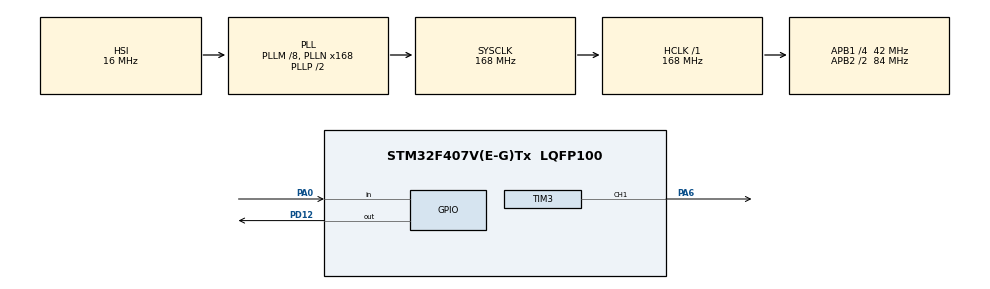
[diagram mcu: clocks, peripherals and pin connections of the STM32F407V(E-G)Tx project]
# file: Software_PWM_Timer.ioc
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Mcu.Family=STM32F4
VP_SYS_VS_tim6.Mode=TIM6
PH0-OSC_IN.Signal=RCC_OSC_IN
RCC.CortexFreq_Value=168000000
FREERTOS.Tasks01=PWMTask,0,128,StartPWMTask,Default,NULL,Dynamic,NULL,NULL
NVIC.TIM6_DAC_IRQn=true\:0\:0\:false\:false\:true\:false\:false\:true
RCC.APB1CLKDivider=RCC_HCLK_DIV4
RCC.SYSCLKSource=RCC_SYSCLKSOURCE_PLLCLK
ProjectManager.StackSize=0x400
PA0-WKUP.Signal=GPIO_Input
ProjectManager.TargetToolchain=STM32CubeIDE
RCC.HCLKFreq_Value=168000000
RCC.APB2TimFreq_Value=168000000
TIM3.Period=100-1
RCC.LSE_VALUE=32768
RCC.AHBFreq_Value=168000000
PH0-OSC_IN.Mode=HSE-External-Oscillator
TIM3.Channel-PWM\ Generation1\ CH1=TIM_CHANNEL_1
RCC.HSE_VALUE=25000000
FREERTOS.configUSE_TIMERS=1
board=custom
RCC.VCOOutputFreq_Value=336000000
RCC.APB2Freq_Value=84000000
TIM3.Prescaler=168-1
PH1-OSC_OUT.Signal=RCC_OSC_OUT
SH.S_TIM3_CH1.0=TIM3_CH1,PWM Generation1 CH1
VP_FREERTOS_VS_CMSIS_V1.Mode=CMSIS_V1
Mcu.Name=STM32F407V(E-G)Tx
FREERTOS.configTIMER_TASK_PRIORITY=6
PH1-OSC_OUT.Mode=HSE-External-Oscillator
RCC.48MHZClocksFreq_Value=84000000
RCC.SYSCLKFreq_VALUE=168000000
Mcu.Package=LQFP100
PA6.Signal=S_TIM3_CH1
NVIC.TimeBase=TIM6_DAC_IRQn
PD12.Signal=GPIO_Output
NVIC.TimeBaseIP=TIM6
ProjectManager.HeapSize=0x200
FREERTOS.Timers01=PeriodicTimer,PTCallback,osTimerPeriodic,Default,NULL,Dynamic,NULL
RCC.HSI_VALUE=16000000
NVIC.PriorityGroup=NVIC_PRIORITYGROUP_4
RCC.APB2CLKDivider=RCC_HCLK_DIV2
RCC.PLLM=8
RCC.PLLN=168
RCC.APB1TimFreq_Value=84000000
RCC.APB1Freq_Value=42000000
VP_TIM3_VS_ClockSourceINT.Mode=Internal

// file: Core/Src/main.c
/* USER CODE BEGIN Header */
/**
  ******************************************************************************
  * @file           : main.c
  * @brief          : Main program body
  ******************************************************************************
  * @attention
  *
  * <h2><center>&copy; Copyright (c) 2021 STMicroelectronics.
  * All rights reserved.</center></h2>
  *
  * This software component is licensed by ST under BSD 3-Clause license,
  * the "License"; You may not use this file except in compliance with the
  * License. You may obtain a copy of the License at:
  *                        opensource.org/licenses/BSD-3-Clause
  *
  ******************************************************************************
  */
/* USER CODE END Header */
#include "main.h"
#include "cmsis_os.h"

/* USER CODE BEGIN PM */
uint16_t increment;
/* USER CODE END PM */

TIM_HandleTypeDef htim3;

osThreadId PWMTaskHandle;
osTimerId PeriodicTimerHandle;

void SystemClock_Config(void);
static void MX_GPIO_Init(void);
static void MX_TIM3_Init(void);
void StartPWMTask(void const * argument);
void PTCallback(void const * argument);

int main(void)
{

  /* MCU Configuration--------------------------------------------------------*/

  /* Reset of all peripherals, Initializes the Flash interface and the Systick. */
  HAL_Init();

  /* Configure the system clock */
  SystemClock_Config();

  /* Initialize all configured peripherals */
  MX_GPIO_Init();
  MX_TIM3_Init();

  /* Create the timer(s) */
  /* definition and creation of PeriodicTimer */
  osTimerDef(PeriodicTimer, PTCallback);
  PeriodicTimerHandle = osTimerCreate(osTimer(PeriodicTimer), osTimerPeriodic, NULL);

  /* Create the thread(s) */
  /* definition and creation of PWMTask */
  osThreadDef(PWMTask, StartPWMTask, osPriorityNormal, 0, 128);
  PWMTaskHandle = osThreadCreate(osThread(PWMTask), NULL);

  /* Start scheduler */
  osKernelStart();

  /* We should never get here as control is now taken by the scheduler */
  /* Infinite loop */
  while (1)
  {

  }
}

void SystemClock_Config(void)
{
  RCC_OscInitTypeDef RCC_OscInitStruct = {0};
  RCC_ClkInitTypeDef RCC_ClkInitStruct = {0};

  /** Configure the main internal regulator output voltage
  */
  __HAL_RCC_PWR_CLK_ENABLE();
  __HAL_PWR_VOLTAGESCALING_CONFIG(PWR_REGULATOR_VOLTAGE_SCALE1);
  /** Initializes the RCC Oscillators according to the specified parameters
  * in the RCC_OscInitTypeDef structure.
  */
  RCC_OscInitStruct.OscillatorType = RCC_OSCILLATORTYPE_HSI;
  RCC_OscInitStruct.HSIState = RCC_HSI_ON;
  RCC_OscInitStruct.HSICalibrationValue = RCC_HSICALIBRATION_DEFAULT;
  RCC_OscInitStruct.PLL.PLLState = RCC_PLL_ON;
  RCC_OscInitStruct.PLL.PLLSource = RCC_PLLSOURCE_HSI;
  RCC_OscInitStruct.PLL.PLLM = 8;
  RCC_OscInitStruct.PLL.PLLN = 168;
  RCC_OscInitStruct.PLL.PLLP = RCC_PLLP_DIV2;
  RCC_OscInitStruct.PLL.PLLQ = 4;
  if (HAL_RCC_OscConfig(&RCC_OscInitStruct) != HAL_OK)
  {
    Error_Handler();
  }
  /** Initializes the CPU, AHB and APB buses clocks
  */
  RCC_ClkInitStruct.ClockType = RCC_CLOCKTYPE_HCLK|RCC_CLOCKTYPE_SYSCLK
                              |RCC_CLOCKTYPE_PCLK1|RCC_CLOCKTYPE_PCLK2;
  RCC_ClkInitStruct.SYSCLKSource = RCC_SYSCLKSOURCE_PLLCLK;
  RCC_ClkInitStruct.AHBCLKDivider = RCC_SYSCLK_DIV1;
  RCC_ClkInitStruct.APB1CLKDivider = RCC_HCLK_DIV4;
  RCC_ClkInitStruct.APB2CLKDivider = RCC_HCLK_DIV2;

  if (HAL_RCC_ClockConfig(&RCC_ClkInitStruct, FLASH_LATENCY_5) != HAL_OK)
  {
    Error_Handler();
  }
}

static void MX_TIM3_Init(void)
{

  TIM_ClockConfigTypeDef sClockSourceConfig = {0};
  TIM_MasterConfigTypeDef sMasterConfig = {0};
  TIM_OC_InitTypeDef sConfigOC = {0};

  htim3.Instance = TIM3;
  htim3.Init.Prescaler = 168-1;
  htim3.Init.CounterMode = TIM_COUNTERMODE_UP;
  htim3.Init.Period = 100-1;
  htim3.Init.ClockDivision = TIM_CLOCKDIVISION_DIV1;
  htim3.Init.AutoReloadPreload = TIM_AUTORELOAD_PRELOAD_DISABLE;
  if (HAL_TIM_Base_Init(&htim3) != HAL_OK)
  {
    Error_Handler();
  }
  sClockSourceConfig.ClockSource = TIM_CLOCKSOURCE_INTERNAL;
  if (HAL_TIM_ConfigClockSource(&htim3, &sClockSourceConfig) != HAL_OK)
  {
    Error_Handler();
  }
  if (HAL_TIM_PWM_Init(&htim3) != HAL_OK)
  {
    Error_Handler();
  }
  sMasterConfig.MasterOutputTrigger = TIM_TRGO_RESET;
  sMasterConfig.MasterSlaveMode = TIM_MASTERSLAVEMODE_DISABLE;
  if (HAL_TIMEx_MasterConfigSynchronization(&htim3, &sMasterConfig) != HAL_OK)
  {
    Error_Handler();
  }
  sConfigOC.OCMode = TIM_OCMODE_PWM1;
  sConfigOC.Pulse = 0;
  sConfigOC.OCPolarity = TIM_OCPOLARITY_HIGH;
  sConfigOC.OCFastMode = TIM_OCFAST_DISABLE;
  if (HAL_TIM_PWM_ConfigChannel(&htim3, &sConfigOC, TIM_CHANNEL_1) != HAL_OK)
  {
    Error_Handler();
  }
  HAL_TIM_MspPostInit(&htim3);

}

static void MX_GPIO_Init(void)
{
  GPIO_InitTypeDef GPIO_InitStruct = {0};

  /* GPIO Ports Clock Enable */
  __HAL_RCC_GPIOH_CLK_ENABLE();
  __HAL_RCC_GPIOA_CLK_ENABLE();
  __HAL_RCC_GPIOD_CLK_ENABLE();

  /*Configure GPIO pin Output Level */
  HAL_GPIO_WritePin(GPIOD, GPIO_PIN_12, GPIO_PIN_RESET);

  /*Configure GPIO pin : PA0 */
  GPIO_InitStruct.Pin = GPIO_PIN_0;
  GPIO_InitStruct.Mode = GPIO_MODE_INPUT;
  GPIO_InitStruct.Pull = GPIO_NOPULL;
  HAL_GPIO_Init(GPIOA, &GPIO_InitStruct);

  /*Configure GPIO pin : PD12 */
  GPIO_InitStruct.Pin = GPIO_PIN_12;
  GPIO_InitStruct.Mode = GPIO_MODE_OUTPUT_PP;
  GPIO_InitStruct.Pull = GPIO_NOPULL;
  GPIO_InitStruct.Speed = GPIO_SPEED_FREQ_LOW;
  HAL_GPIO_Init(GPIOD, &GPIO_InitStruct);

}

void StartPWMTask(void const * argument)
{
  /* USER CODE BEGIN 5 */
	osTimerStart(PeriodicTimerHandle, 1000);
	htim3.Instance->CCR1=50;
  /* Infinite loop */
  for(;;)
  {
	  if(!(HAL_GPIO_ReadPin(GPIOA, GPIO_PIN_0)))
	  {
		  while(!(HAL_GPIO_ReadPin(GPIOA, GPIO_PIN_0)))
		  {
			  HAL_GPIO_WritePin(GPIOD, GPIO_PIN_12, 1);
			  htim3.Instance->CCR1=increment;
			  increment+=10;
			  if(increment>100)
				  increment =0;
		  }
	  }
    osDelay(1);
  }
  /* USER CODE END 5 */
}

/* PTCallback function */
void PTCallback(void const * argument)
{
  /* USER CODE BEGIN PTCallback */
	HAL_GPIO_WritePin(GPIOD, GPIO_PIN_12, 0);
  /* USER CODE END PTCallback */
}

 /**
  * @brief  Period elapsed callback in non blocking mode
  * @note   This function is called  when TIM6 interrupt took place, inside
  * HAL_TIM_IRQHandler(). It makes a direct call to HAL_IncTick() to increment
  * a global variable "uwTick" used as application time base.
  * @param  htim : TIM handle
  * @retval None
  */
void HAL_TIM_PeriodElapsedCallback(TIM_HandleTypeDef *htim)
{
  if (htim->Instance == TIM6) {
    HAL_IncTick();
  }
}

void Error_Handler(void)
{
  __disable_irq();
  while (1)
  {
  }
}

/************************ (C) COPYRIGHT STMicroelectronics *****END OF FILE****/
